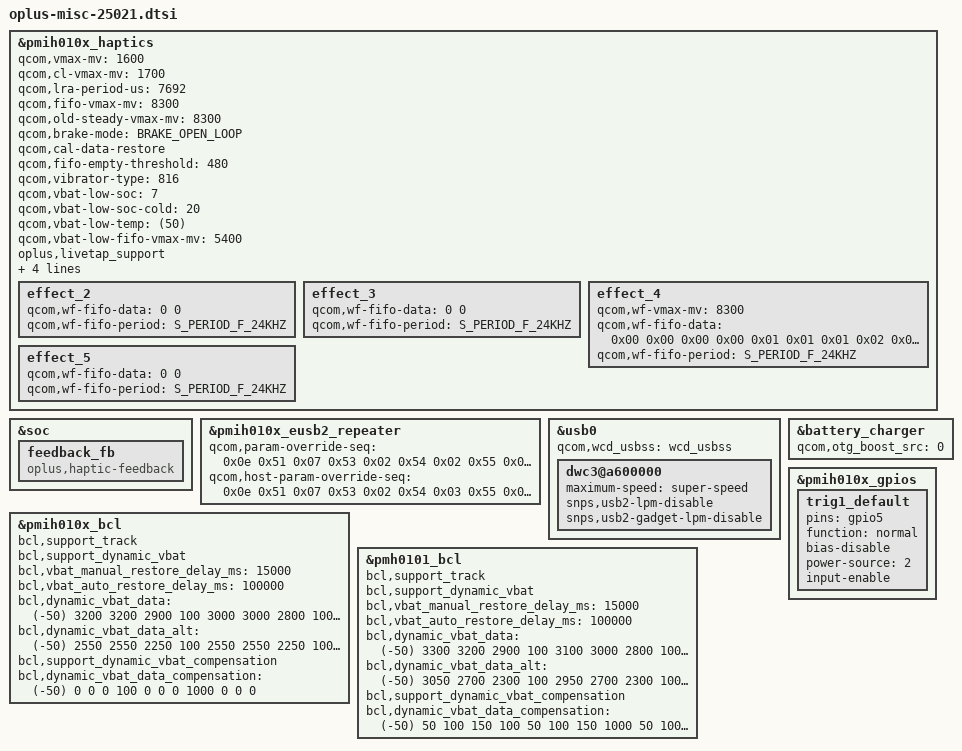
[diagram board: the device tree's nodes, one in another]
&pmih010x_haptics {
	qcom,vmax-mv = <1600>;
	qcom,cl-vmax-mv = <1700>;
	qcom,lra-period-us = <7692>;
	qcom,fifo-vmax-mv = <8300>;
	qcom,old-steady-vmax-mv = <8300>;
	qcom,brake-mode = <BRAKE_OPEN_LOOP>;
	qcom,cal-data-restore;
	qcom,fifo-empty-threshold = <480>;
	qcom,vibrator-type = <816>;//0816B
	qcom,vbat-low-soc = <7>;
	qcom,vbat-low-soc-cold = <20>;
	qcom,vbat-low-temp = <(50)>;/*5C*/
	qcom,vbat-low-fifo-vmax-mv = <5400>;
	oplus,livetap_support;
	oplus,trig_support;
	interrupt-parent = <&spmi1_bus>;
	oplus,trig1-gpio = <&pmih010x_gpios 5 GPIO_ACTIVE_LOW>;
	pinctrl-names = "default";
	pinctrl-0 = <&trig1_default>;
	/delete-node/ effect_0;
	/delete-node/ effect_1;
	/delete-node/ primitive_0;
	/delete-node/ primitive_1;
	/delete-node/ primitive_2;
	/delete-node/ primitive_3;
	/delete-node/ primitive_4;
	/delete-node/ primitive_5;
	/delete-node/ primitive_6;
	/delete-node/ primitive_7;
	/delete-node/ primitive_8;
	effect_2 { /* trig3 */
		qcom,wf-fifo-data = /bits/ 8 <0 0>;
		qcom,wf-fifo-period = <S_PERIOD_F_24KHZ>;
	};
	effect_3 { /* trig2 */
		qcom,wf-fifo-data = /bits/ 8 <0 0>;
		qcom,wf-fifo-period = <S_PERIOD_F_24KHZ>;
	};
	effect_4 { /* trig1 */
		qcom,wf-vmax-mv = <8300>;
		qcom,wf-fifo-data = /bits/ 8 <0x00 0x00 0x00 0x00 0x01 0x01 0x01 0x02 0x02 0x03
			0x03 0x04 0x05 0x06 0x08 0x09 0x0b 0x0e 0x10 0x12
			0x15 0x18 0x1b 0x1f 0x22 0x26 0x2a 0x2f 0x33 0x38
			0x3c 0x40 0x45 0x4a 0x4e 0x53 0x58 0x5c 0x60 0x64
			0x68 0x6b 0x6e 0x71 0x73 0x75 0x77 0x78 0x7a 0x7a
			0x7a 0x7a 0x79 0x78 0x77 0x76 0x74 0x71 0x6e 0x6b
			0x67 0x62 0x5d 0x57 0x51 0x4a 0x43 0x3c 0x34 0x2c
			0x23 0x19 0x10 0x06 0xfe 0xf5 0xec 0xe2 0xd9 0xd0
			0xc8 0xc0 0xb8 0xb1 0xab 0xa5 0xa0 0x9c 0x98 0x94
			0x91 0x8f 0x8d 0x8b 0x8b 0x8b 0x8b 0x8d 0x8e 0x91
			0x93 0x96 0x9a 0x9f 0xa4 0xa9 0xb0 0xb6 0xbe 0xc5
			0xcd 0xd5 0xde 0xe8 0xf1 0xfb 0x03 0x0d 0x17 0x20
			0x2a 0x33 0x3c 0x44 0x4c 0x53 0x5a 0x60 0x66 0x6c
			0x70 0x74 0x77 0x79 0x7b 0x7c 0x7d 0x7e 0x7d 0x7c
			0x7a 0x77 0x74 0x70 0x6b 0x66 0x60 0x5a 0x53 0x4b
			0x43 0x3a 0x31 0x28 0x1e 0x13 0x09 0x00 0xf6 0xec
			0xe3 0xda 0xd2 0xcb 0xc4 0xbd 0xb9 0xb4 0xb1 0xae
			0xac 0xab 0xab 0xab 0xac 0xae 0xb0 0xb3 0xb6 0xb9
			0xbc 0xbf 0xc2 0xc5 0xc9 0xcc 0xcf 0xd2 0xd5 0xd8
			0xda 0xdd 0xdf 0xe1 0xe3 0xe5 0xe6 0xe8 0xe9 0xea
			0xeb 0xec 0xec 0xed 0xee 0xee 0xef 0xf0 0xf0 0xf1
			0xf1 0xf1 0xf2 0xf2 0xf2 0xf3 0xf3 0xf3 0xf3 0xf4
			0xf4 0xf4 0xf4 0xf5 0xf5 0xf5 0xf5 0xf5 0xf5 0xf6
			0xf6 0xf6 0xf6 0xf6 0xf6 0xf6 0xf6 0xf7 0xf7 0xf7
			0xf7 0xf7 0xf7 0xf7 0xf7 0xf7 0xf8 0xf8 0xf8 0xf8
			0xf8 0xf9 0xf9 0xf9 0xf9 0xf9 0xf9 0xf9 0xf9 0xf9
			0xfa 0xfa 0xfa 0xfa 0xfa 0xfa 0xfa 0xfa 0xfa 0xfa
			0xfa 0xfa 0xfa 0xfa 0xfb 0xfb 0xfb 0xfb 0xfb 0xfc
			0xfc 0xfc 0xfc 0xfc 0xfc 0xfc 0xfc 0xfc 0xfc 0xfc
			0xfc 0xfc 0xfc 0xfd 0xfd 0xfd 0xfd 0xfd 0xfd 0xfd
			0xfd 0xfd 0xfd 0xfd 0xfd 0xfd 0xfd 0xfd 0xfd 0xfd
			0xfd 0xfd 0xfd 0xfd 0xfd 0xfe 0xfe 0xfe 0xfe 0xfe
			0xfe 0xfe 0xfe 0xfe 0xfe 0xfe 0xfe 0xfe 0xfe 0xfe
			0xfe 0xfe 0xfe 0xfe 0xfe 0xfe 0xfe 0xfe 0xfe 0xfe
			0xfe 0xfe 0xfe 0xfe 0xfe 0xfe 0xfd 0xfe 0xfe 0xfe
			0xfe 0xfe 0xfe 0xfe 0xfe 0xfe 0xfe 0xfe 0xfe 0xfe
			0xfe 0xfe 0xfe 0xfe 0xfe 0xfe 0xfe 0xfe 0xfe 0xfe
			0xfe 0xfe 0xfe 0xfe 0xfe 0xfe 0xfe 0xfe 0xfe 0xfe
			0xfe 0xfe 0xfe 0xfe 0xfe 0xfe 0xfe 0xfe 0xfe 0xfe
			0xfe 0xfe>;
		qcom,wf-fifo-period = <S_PERIOD_F_24KHZ>;
	};
	effect_5 {
		qcom,wf-fifo-data = /bits/ 8 <0 0>;
		qcom,wf-fifo-period = <S_PERIOD_F_24KHZ>;
	};
};

&soc {
	feedback_fb: feedback_fb {
		compatible = "oplus,haptic-feedback";
	};
};

&pmih010x_eusb2_repeater {
	qcom,param-override-seq = <0x0e 0x51 0x07 0x53 0x02 0x54 0x02 0x55 0x07 0x57>;
	qcom,host-param-override-seq = <0x0e 0x51 0x07 0x53 0x02 0x54 0x03 0x55 0x07 0x57>;
};

&usb0 {
	qcom,wcd_usbss = <&wcd_usbss>;
	dwc3@a600000 {
		maximum-speed = "super-speed";
		snps,usb2-lpm-disable;
		snps,usb2-gadget-lpm-disable;
	};
};

&battery_charger {
	qcom,otg_boost_src = <0>; /* 0:plat_pmic 1:external */
};

&pmih010x_bcl {
    bcl,support_track;
    bcl,support_dynamic_vbat;
    bcl,vbat_manual_restore_delay_ms = <15000>;
    bcl,vbat_auto_restore_delay_ms = <100000>;
    bcl,dynamic_vbat_data =  <(-50) 3200 3200 2900
                100 3000 3000 2800
                1000 2900 2900 2700>;
    bcl,dynamic_vbat_data_alt = <(-50) 2550 2550 2250
                100 2550 2550 2250
                1000 2550 2550 2250>;
    bcl,support_dynamic_vbat_compensation;
    bcl,dynamic_vbat_data_compensation = <(-50) 0 0 0
                100 0 0 0
                1000 0 0 0>;
};

&pmh0101_bcl {
    bcl,support_track;
    bcl,support_dynamic_vbat;
    bcl,vbat_manual_restore_delay_ms = <15000>;
    bcl,vbat_auto_restore_delay_ms = <100000>;
    bcl,dynamic_vbat_data = <(-50) 3300 3200 2900
                100 3100 3000 2800
                1000 3100 2900 2700>;
    bcl,dynamic_vbat_data_alt = <(-50) 3050 2700 2300
                100 2950 2700 2300
                1000 2850 2700 2300>;
    bcl,support_dynamic_vbat_compensation;
    bcl,dynamic_vbat_data_compensation = <(-50) 50 100 150
                100 50 100 150
                1000 50 100 150>;
};

&pmih010x_gpios {
	trig1_default: trig1_default {
		pins = "gpio5"; /* GPIO 5 */
		function = "normal"; /* normal input */
		bias-disable; /* NO pull */
		power-source = <2>; /* 1.2V */
		input-enable; /* digital input */
	};
};
